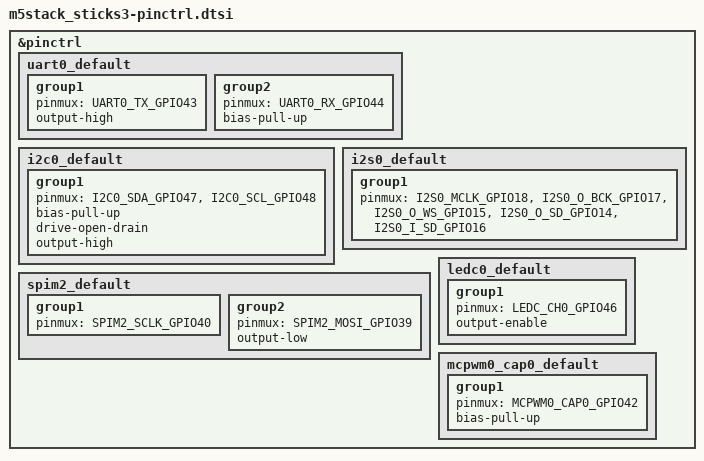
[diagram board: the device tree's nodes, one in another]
/*
 * Copyright (c) 2026
 *
 * SPDX-License-Identifier: Apache-2.0
 *
 * Pin assignments derived from the M5Stack StickS3 official PinMap
 * (docs.m5stack.com/en/core/StickS3). See docs/00_RESEARCH_SNAPSHOT.md and
 * docs/adr/0002-pin-map-source-of-truth.md.
 */

#include <zephyr/dt-bindings/pinctrl/esp-pinctrl-common.h>
#include <zephyr/dt-bindings/pinctrl/esp32s3-pinctrl.h>
#include <zephyr/dt-bindings/pinctrl/esp32s3-gpio-sigmap.h>

&pinctrl {
	uart0_default: uart0_default {
		group1 {
			pinmux = <UART0_TX_GPIO43>;
			output-high;
		};

		group2 {
			pinmux = <UART0_RX_GPIO44>;
			bias-pull-up;
		};
	};

	/* M5Stack PinMap: SDA G47, SCL G48 (BMI270 / M5PM1). */
	i2c0_default: i2c0_default {
		group1 {
			pinmux = <I2C0_SDA_GPIO47>,
				 <I2C0_SCL_GPIO48>;
			bias-pull-up;
			drive-open-drain;
			output-high;
		};
	};

	/*
	 * I2S0 to the ES8311 codec (hardware-verified StickS3 pins):
	 *   MCLK         G18  (codec master clock out)
	 *   BCLK (O_BCK) G17  (bit clock)
	 *   WS   (O_WS)  G15  (word select / LRCK)
	 *   DOUT (O_SD)  G14  (SoC->codec, DSDIN at the codec)
	 *   DIN  (I_SD)  G16  (codec->SoC, ASDOUT at the codec)
	 * The SoC is the I2S master, so MCLK/BCLK/WS/DOUT are outputs and DIN is
	 * the only input. MCLK is derived from BCLK at the codec (MCLK = 256*Fs).
	 */
	i2s0_default: i2s0_default {
		group1 {
			pinmux = <I2S0_MCLK_GPIO18>,
				 <I2S0_O_BCK_GPIO17>,
				 <I2S0_O_WS_GPIO15>,
				 <I2S0_O_SD_GPIO14>,
				 <I2S0_I_SD_GPIO16>;
		};
	};

	/* M5Stack PinMap: LCD MOSI G39, SCK G40 (CS G41 handled as GPIO). */
	spim2_default: spim2_default {
		group1 {
			pinmux = <SPIM2_SCLK_GPIO40>;
		};

		group2 {
			pinmux = <SPIM2_MOSI_GPIO39>;
			output-low;
		};
	};

	/*
	 * IR (NEC) over stock PWM peripherals (Zephyr 4.4 has no ESP32 RMT
	 * driver). IR_TX on G46 via the LEDC carrier output; IR_RX on G42 via
	 * MCPWM capture 0 input. Pins from the StickS3 PinMap (IR_TX G46,
	 * IR_RX G42, see docs/00_RESEARCH_SNAPSHOT.md).
	 */
	ledc0_default: ledc0_default {
		group1 {
			pinmux = <LEDC_CH0_GPIO46>;
			output-enable;
		};
	};

	mcpwm0_cap0_default: mcpwm0_cap0_default {
		group1 {
			pinmux = <MCPWM0_CAP0_GPIO42>;
			bias-pull-up;
		};
	};
};
